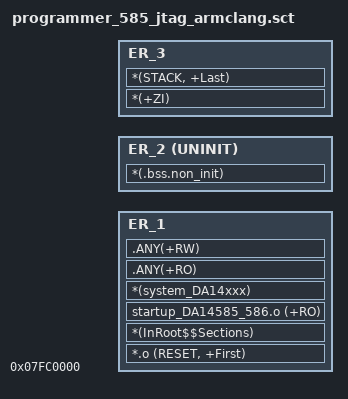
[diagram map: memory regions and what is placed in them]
LR_1 0x07FC0000 15*1024 {
    ER_1 +0 {
       *.o (RESET, +First)
       *(InRoot$$Sections)
       startup_DA14585_586.o (+RO)
       *(system_DA14xxx)
       .ANY(+RO)
       .ANY(+RW)
    }

    ER_2 AlignExpr(+0,8) UNINIT {
       *(.bss.non_init)
    }

; The address space after 0x07FC7C00 is used by SmartSnippets Toolbox for commands and data
; and must not be overwritten by application code
    ER_3 +0 (0x07FC7C00 - ImageLimit(ER_2)) {
       *(+ZI)
       *(STACK, +Last)
    }
}
